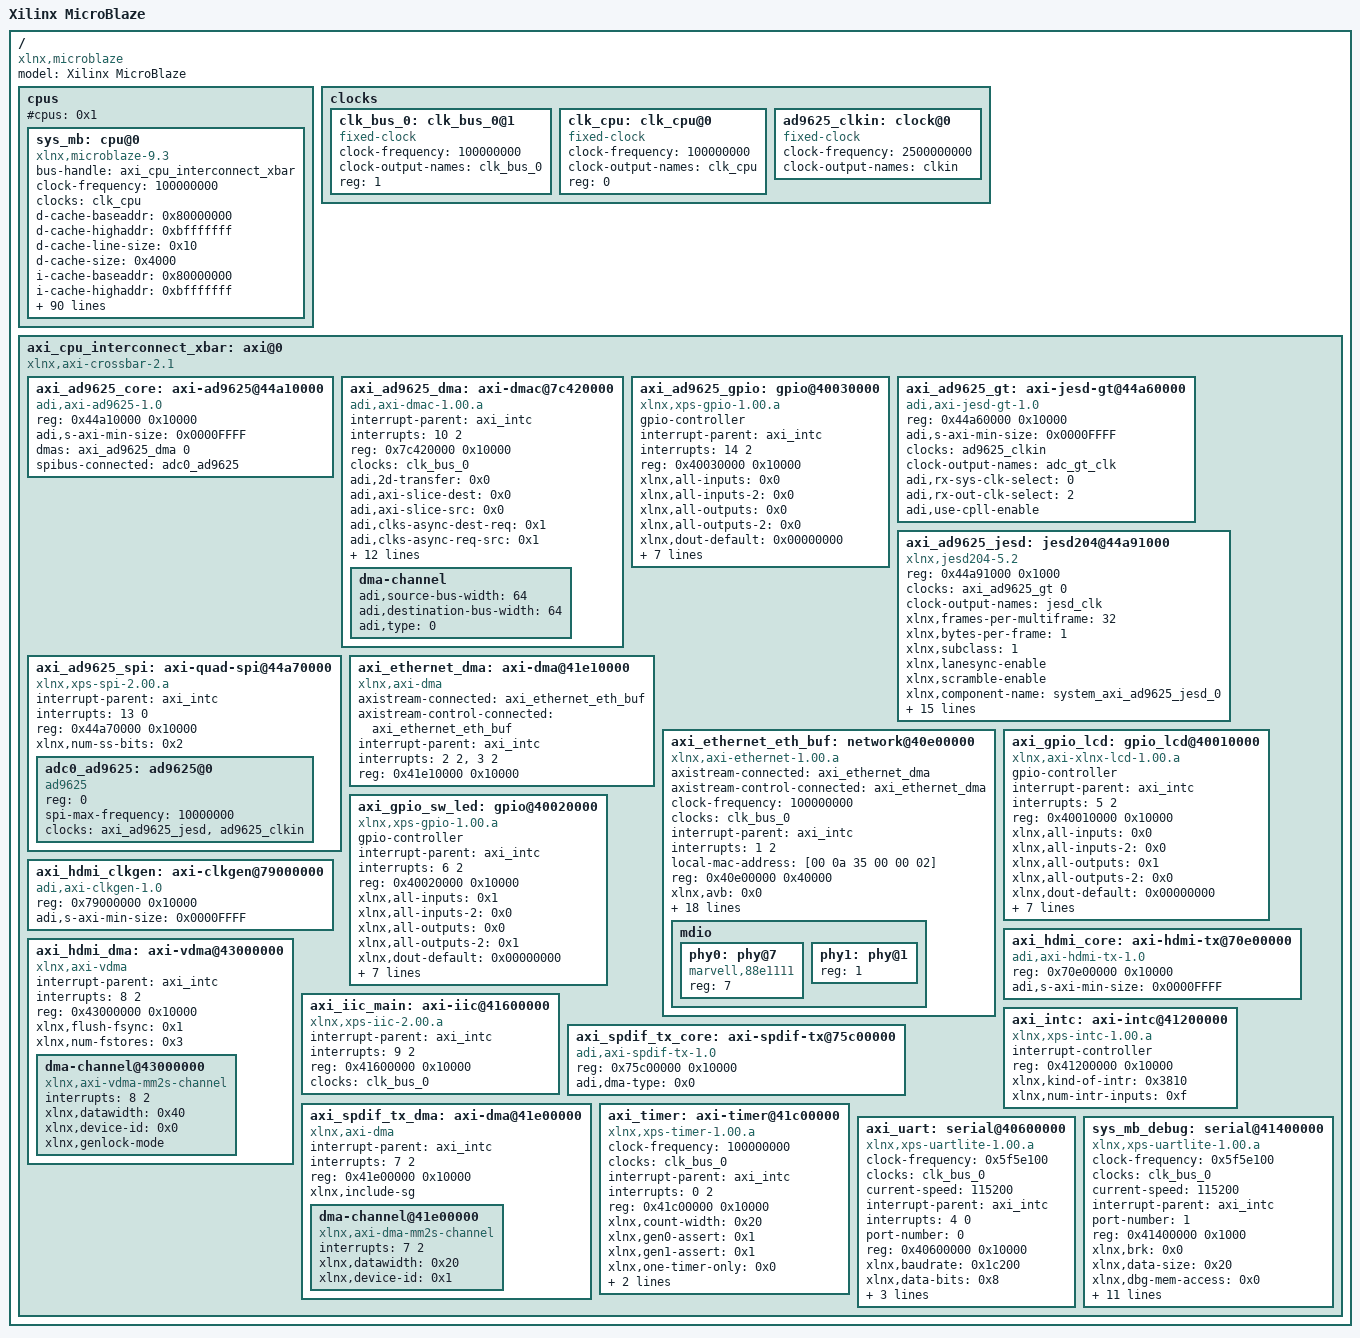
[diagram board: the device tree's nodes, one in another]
/*
 * CAUTION: This file is automatically generated by Xilinx.
 * Version:
 * Today is: Tue Sep  9 10:06:07 2014
*/

/{
	#address-cells = <1>;
	#size-cells = <1>;
	compatible = "xlnx,microblaze";
	model = "Xilinx MicroBlaze";
	cpus {
		#address-cells = <1>;
		#cpus = <0x1>;
		#size-cells = <0>;
		sys_mb: cpu@0 {
			bus-handle = <&axi_cpu_interconnect_xbar>;
			clock-frequency = <100000000>;
			clocks = <&clk_cpu>;
			compatible = "xlnx,microblaze-9.3";
			d-cache-baseaddr = <0x80000000>;
			d-cache-highaddr = <0xbfffffff>;
			d-cache-line-size = <0x10>;
			d-cache-size = <0x4000>;
			device_type = "cpu";
			i-cache-baseaddr = <0x80000000>;
			i-cache-highaddr = <0xbfffffff>;
			i-cache-line-size = <0x20>;
			i-cache-size = <0x4000>;
			interrupt-handle = <&axi_intc>;
			model = "microblaze,9.3";
			timebase-frequency = <100000000>;
			xlnx,addr-tag-bits = <0x10>;
			xlnx,allow-dcache-wr = <0x1>;
			xlnx,allow-icache-wr = <0x1>;
			xlnx,area-optimized = <0x0>;
			xlnx,async-interrupt = <0x1>;
			xlnx,avoid-primitives = <0x0>;
			xlnx,base-vectors = <0x00000000>;
			xlnx,branch-target-cache-size = <0x0>;
			xlnx,cache-byte-size = <0x4000>;
			xlnx,d-axi = <0x1>;
			xlnx,d-lmb = <0x1>;
			xlnx,data-size = <0x20>;
			xlnx,dcache-addr-tag = <0x10>;
			xlnx,dcache-always-used = <0x1>;
			xlnx,dcache-byte-size = <0x4000>;
			xlnx,dcache-data-width = <0x0>;
			xlnx,dcache-force-tag-lutram = <0x0>;
			xlnx,dcache-line-len = <0x4>;
			xlnx,dcache-use-writeback = <0x0>;
			xlnx,dcache-victims = <0x8>;
			xlnx,debug-counter-width = <0x20>;
			xlnx,debug-enabled = <0x1>;
			xlnx,debug-event-counters = <0x5>;
			xlnx,debug-latency-counters = <0x1>;
			xlnx,debug-profile-size = <0x0>;
			xlnx,debug-trace-size = <0x2000>;
			xlnx,div-zero-exception = <0x1>;
			xlnx,dynamic-bus-sizing = <0x0>;
			xlnx,ecc-use-ce-exception = <0x0>;
			xlnx,edge-is-positive = <0x0>;
			xlnx,enable-discrete-ports = <0x0>;
			xlnx,endianness = <0x1>;
			xlnx,fault-tolerant = <0x0>;
			xlnx,fpu-exception = <0x0>;
			xlnx,freq = <0x5f5e100>;
			xlnx,fsl-exception = <0x0>;
			xlnx,fsl-links = <0x0>;
			xlnx,i-axi = <0x0>;
			xlnx,i-lmb = <0x1>;
			xlnx,icache-always-used = <0x1>;
			xlnx,icache-data-width = <0x0>;
			xlnx,icache-force-tag-lutram = <0x0>;
			xlnx,icache-line-len = <0x8>;
			xlnx,icache-streams = <0x1>;
			xlnx,icache-victims = <0x8>;
			xlnx,ill-opcode-exception = <0x1>;
			xlnx,interconnect = <0x2>;
			xlnx,interrupt-is-edge = <0x0>;
			xlnx,lockstep-select = <0x0>;
			xlnx,lockstep-slave = <0x0>;
			xlnx,mmu-dtlb-size = <0x4>;
			xlnx,mmu-itlb-size = <0x2>;
			xlnx,mmu-privileged-instr = <0x0>;
			xlnx,mmu-tlb-access = <0x3>;
			xlnx,mmu-zones = <0x2>;
			xlnx,number-of-pc-brk = <0x1>;
			xlnx,number-of-rd-addr-brk = <0x0>;
			xlnx,number-of-wr-addr-brk = <0x0>;
			xlnx,opcode-0x0-illegal = <0x1>;
			xlnx,optimization = <0x0>;
			xlnx,pc-width = <0x20>;
			xlnx,pvr = <0x2>;
			xlnx,pvr-user1 = <0x00>;
			xlnx,pvr-user2 = <0x00000000>;
			xlnx,reset-msr = <0x00000000>;
			xlnx,sco = <0x0>;
			xlnx,trace = <0x0>;
			xlnx,unaligned-exceptions = <0x1>;
			xlnx,use-barrel = <0x1>;
			xlnx,use-branch-target-cache = <0x0>;
			xlnx,use-config-reset = <0x0>;
			xlnx,use-dcache = <0x1>;
			xlnx,use-div = <0x1>;
			xlnx,use-ext-brk = <0x0>;
			xlnx,use-ext-nm-brk = <0x0>;
			xlnx,use-extended-fsl-instr = <0x0>;
			xlnx,use-fpu = <0x0>;
			xlnx,use-hw-mul = <0x2>;
			xlnx,use-icache = <0x1>;
			xlnx,use-interrupt = <0x1>;
			xlnx,use-mmu = <0x3>;
			xlnx,use-msr-instr = <0x1>;
			xlnx,use-pcmp-instr = <0x1>;
			xlnx,use-reorder-instr = <0x1>;
			xlnx,use-stack-protection = <0x0>;
		} ;
	} ;
	clocks {
		#address-cells = <1>;
		#size-cells = <0>;
		clk_bus_0: clk_bus_0@1 {
			#clock-cells = <0>;
			clock-frequency = <100000000>;
			clock-output-names = "clk_bus_0";
			compatible = "fixed-clock";
			reg = <1>;
		} ;
		clk_cpu: clk_cpu@0 {
			#clock-cells = <0>;
			clock-frequency = <100000000>;
			clock-output-names = "clk_cpu";
			compatible = "fixed-clock";
			reg = <0>;
		} ;
		ad9625_clkin: clock@0 {
			#clock-cells = <0>;
			compatible = "fixed-clock";
			clock-frequency = <2500000000>;
			clock-output-names = "clkin";
		};
	} ;
	axi_cpu_interconnect_xbar: axi@0 {
		#address-cells = <1>;
		#size-cells = <1>;
		compatible = "xlnx,axi-crossbar-2.1", "simple-bus";
		ranges ;
		axi_ad9625_core: axi-ad9625@44a10000 {
			compatible = "adi,axi-ad9625-1.0";
			reg = <0x44a10000 0x10000>;
			adi,s-axi-min-size = <0x0000FFFF>;
			dmas = <&axi_ad9625_dma 0>;
			dma-names = "rx";
			spibus-connected = <&adc0_ad9625>;
		} ;

		axi_ad9625_dma: axi-dmac@7c420000 {
			#dma-cells = <1>;
			compatible = "adi,axi-dmac-1.00.a";
			interrupt-parent = <&axi_intc>;
			interrupts = <10 2>;
			reg = <0x7c420000 0x10000>;
			clocks = <&clk_bus_0>;
			adi,2d-transfer = <0x0>;
			adi,axi-slice-dest = <0x0>;
			adi,axi-slice-src = <0x0>;
			adi,clks-async-dest-req = <0x1>;
			adi,clks-async-req-src = <0x1>;
			adi,clks-async-src-dest = <0x1>;
			adi,cyclic = <0x0>;
			adi,dma-axi-protocol-dest = <0x0>;
			adi,dma-axi-protocol-src = <0x0>;
			adi,dma-data-width-dest = <0x100>;
			adi,dma-data-width-src = <0x100>;
			adi,dma-length-width = <0x18>;
			adi,dma-type-dest = <0x0>;
			adi,dma-type-src = <0x2>;
			adi,fifo-size = <0x4>;
			adi,max-bytes-per-burst = <0x80>;
			adi,sync-transfer-start = <0x1>;

			dma-channel {
				adi,source-bus-width = <64>;
				adi,destination-bus-width = <64>;
				//adi,buswidth = <256>;
				adi,type = <0>;
			};
		} ;
		axi_ad9625_gpio: gpio@40030000 {
			#gpio-cells = <2>;
			compatible = "xlnx,xps-gpio-1.00.a";
			gpio-controller ;
			interrupt-parent = <&axi_intc>;
			interrupts = <14 2>;
			reg = <0x40030000 0x10000>;
			xlnx,all-inputs = <0x0>;
			xlnx,all-inputs-2 = <0x0>;
			xlnx,all-outputs = <0x0>;
			xlnx,all-outputs-2 = <0x0>;
			xlnx,dout-default = <0x00000000>;
			xlnx,dout-default-2 = <0x00000000>;
			xlnx,gpio-width = <0x2>;
			xlnx,gpio2-width = <0x20>;
			xlnx,interrupt-present = <0x1>;
			xlnx,is-dual = <0x0>;
			xlnx,tri-default = <0xFFFFFFFF>;
			xlnx,tri-default-2 = <0xFFFFFFFF>;
		} ;
		axi_ad9625_gt: axi-jesd-gt@44a60000 {
			#clock-cells = <1>;
			compatible = "adi,axi-jesd-gt-1.0";
			reg = <0x44a60000 0x10000>;
			adi,s-axi-min-size = <0x0000FFFF>;

			clocks = <&ad9625_clkin>;
			clock-names = "adc_clk";
			clock-output-names = "adc_gt_clk";

			adi,rx-sys-clk-select = <0>;
			adi,rx-out-clk-select = <2>;
			adi,use-cpll-enable;

		} ;
		axi_ad9625_jesd: jesd204@44a91000 {
			#clock-cells = <0>;
			compatible = "xlnx,jesd204-5.2";
			reg = <0x44a91000 0x1000>;

			clocks = <&axi_ad9625_gt 0>;
			clock-names = "gt_clk";
			clock-output-names = "jesd_clk";

			xlnx,frames-per-multiframe = <32>;
			xlnx,bytes-per-frame = <1>;
			xlnx,subclass = <1>;
			xlnx,lanesync-enable;
			xlnx,scramble-enable;

			xlnx,component-name = "system_axi_ad9625_jesd_0";
			xlnx,drpclk-freq = "200.0";
			xlnx,elaboration-transient-dir = <0x0>;
			xlnx,gt-line-rate = "6.25";
			xlnx,gt-refclk-freq = "156.25";
			xlnx,lanes = <0x8>;
			xlnx,lmfc-buffer-size = <0x6>;
			xlnx,node-is-transmit = <0x0>;
			xlnx,pll-selection = <0x0>;
			xlnx,speedgrade = "-2";
			xlnx,supportlevel = <0x0>;
			xlnx,sysref-sampling-edge = <0x0>;
			xlnx,transceivercontrol = "false";
			xlnx,use-bram = <0x1>;
			xlnx,use-jspat = "false";
			xlnx,use-rpat = "false";
		} ;
		axi_ad9625_spi: axi-quad-spi@44a70000 {
			#address-cells = <1>;
			#size-cells = <0>;
			compatible = "xlnx,xps-spi-2.00.a";
			interrupt-parent = <&axi_intc>;
			interrupts = <13 0>;
			reg = <0x44a70000 0x10000>;
			xlnx,num-ss-bits = <0x2>;

			adc0_ad9625: ad9625@0 {
				#address-cells = <1>;
				#size-cells = <0>;
				compatible = "ad9625";
				reg = <0>;
				spi-max-frequency = <10000000>;
				clocks = <&axi_ad9625_jesd>, <&ad9625_clkin>;
				clock-names = "jesd_clk", "adc_clk";

			};

		} ;
		axi_ethernet_dma: axi-dma@41e10000 {
			axistream-connected = <&axi_ethernet_eth_buf>;
			axistream-control-connected = <&axi_ethernet_eth_buf>;
			compatible = "xlnx,axi-dma";
			interrupt-parent = <&axi_intc>;
			interrupts = <2 2>, <3 2>;
			reg = <0x41e10000 0x10000>;
		} ;
		axi_ethernet_eth_buf: network@40e00000 {
// 			axistream-connected = <&axi_ethernet_dma>;
// 			axistream-control-connected = <&axi_ethernet_dma>;
// 			clock-frequency = <100000000>;
// 			clocks = <&clk_bus_0>;
// 			compatible = "xlnx,axi-ethernet-1.00.a";
// 			device_type = "network";
// 			interrupt-parent = <&axi_intc>;
// 			interrupts = <1 2>;
// 			local-mac-address = [00 0a 35 00 00 00];
// 			reg = <0x40e00000 0x40000>;
// 			phy-handle = <&phy0 &phy1>;
// 			xlnx,avb = <0x0>;
// 			xlnx,enable-lvds = <0x0>;
// 			xlnx,mcast-extend = <0x0>;
// 			xlnx,phy-type = <0x4>;
// 			xlnx,phyaddr = <0x1>;
// 			xlnx,rxcsum = <0x2>;
// 			xlnx,rxmem = <0x1000>;
// 			xlnx,rxvlan-strp = <0x0>;
// 			xlnx,rxvlan-tag = <0x0>;
// 			xlnx,rxvlan-tran = <0x0>;
// 			xlnx,stats = <0x1>;
// 			xlnx,temac-addr-width = <0xc>;
// 			xlnx,txcsum = <0x2>;
// 			xlnx,txmem = <0x1000>;
// 			xlnx,txvlan-strp = <0x0>;
// 			xlnx,txvlan-tag = <0x0>;
// 			xlnx,txvlan-tran = <0x0>;
// 			xlnx,type = <0x1>;


			axistream-connected = <&axi_ethernet_dma>;
			axistream-control-connected = <&axi_ethernet_dma>;
			clock-frequency = <100000000>;
			clocks = <&clk_bus_0>;
			compatible = "xlnx,axi-ethernet-1.00.a";
			device_type = "network";
			interrupt-parent = <&axi_intc>;
			interrupts = <1 2>;
			local-mac-address = [00 0a 35 00 00 02];
			reg = <0x40e00000 0x40000>;
			xlnx,avb = <0x0>;
			xlnx,enable-lvds = <0x0>;
			xlnx,mcast-extend = <0x0>;
			xlnx,phy-type = <0x4>;
			xlnx,phyaddr = <0x1>;
			xlnx,rxcsum = <0x2>;
			xlnx,rxmem = <0x2000>;
			xlnx,rxvlan-strp = <0x0>;
			xlnx,rxvlan-tag = <0x0>;
			xlnx,rxvlan-tran = <0x0>;
			xlnx,stats = <0x1>;
			xlnx,temac-addr-width = <0xc>;
			xlnx,txcsum = <0x2>;
			xlnx,txmem = <0x2000>;
			xlnx,txvlan-strp = <0x0>;
			xlnx,txvlan-tag = <0x0>;
			xlnx,txvlan-tran = <0x0>;
			xlnx,type = <0x1>;
			phy-handle = <&phy0 &phy1>;

			mdio {
				#address-cells = <1>;
				#size-cells = <0>;
				phy0: phy@7 {
					compatible = "marvell,88e1111";
					device_type = "ethernet-phy";
					reg = <7>;
				} ;
				phy1: phy@1 {
					device_type = "ethernet-phy";
					reg = <1>;
				} ;

			} ;
		} ;
		axi_gpio_lcd: gpio_lcd@40010000 {
			#gpio-cells = <2>;
			compatible = "xlnx,axi-xlnx-lcd-1.00.a";
			gpio-controller ;
			interrupt-parent = <&axi_intc>;
			interrupts = <5 2>;
			reg = <0x40010000 0x10000>;
			xlnx,all-inputs = <0x0>;
			xlnx,all-inputs-2 = <0x0>;
			xlnx,all-outputs = <0x1>;
			xlnx,all-outputs-2 = <0x0>;
			xlnx,dout-default = <0x00000000>;
			xlnx,dout-default-2 = <0x00000000>;
			xlnx,gpio-width = <0x7>;
			xlnx,gpio2-width = <0x20>;
			xlnx,interrupt-present = <0x1>;
			xlnx,is-dual = <0x0>;
			xlnx,tri-default = <0xFFFFFFFF>;
			xlnx,tri-default-2 = <0xFFFFFFFF>;
		} ;
		axi_gpio_sw_led: gpio@40020000 {
			#gpio-cells = <2>;
			compatible = "xlnx,xps-gpio-1.00.a";
			gpio-controller ;
			interrupt-parent = <&axi_intc>;
			interrupts = <6 2>;
			reg = <0x40020000 0x10000>;
			xlnx,all-inputs = <0x1>;
			xlnx,all-inputs-2 = <0x0>;
			xlnx,all-outputs = <0x0>;
			xlnx,all-outputs-2 = <0x1>;
			xlnx,dout-default = <0x00000000>;
			xlnx,dout-default-2 = <0x00000000>;
			xlnx,gpio-width = <0xd>;
			xlnx,gpio2-width = <0x8>;
			xlnx,interrupt-present = <0x1>;
			xlnx,is-dual = <0x1>;
			xlnx,tri-default = <0xFFFFFFFF>;
			xlnx,tri-default-2 = <0xFFFFFFFF>;
		} ;
		axi_hdmi_clkgen: axi-clkgen@79000000 {
			compatible = "adi,axi-clkgen-1.0";
			reg = <0x79000000 0x10000>;
			adi,s-axi-min-size = <0x0000FFFF>;
		} ;
		axi_hdmi_core: axi-hdmi-tx@70e00000 {
			compatible = "adi,axi-hdmi-tx-1.0";
			reg = <0x70e00000 0x10000>;
			adi,s-axi-min-size = <0x0000FFFF>;
		} ;
		axi_hdmi_dma: axi-vdma@43000000 {
			compatible = "xlnx,axi-vdma";
			interrupt-parent = <&axi_intc>;
			interrupts = <8 2>;
			reg = <0x43000000 0x10000>;
			xlnx,flush-fsync = <0x1>;
			xlnx,num-fstores = <0x3>;
			dma-channel@43000000 {
				compatible = "xlnx,axi-vdma-mm2s-channel";
				interrupts = <8 2>;
				xlnx,datawidth = <0x40>;
				xlnx,device-id = <0x0>;
				xlnx,genlock-mode ;
			} ;
		} ;
		axi_iic_main: axi-iic@41600000 {
			#address-cells = <1>;
			#size-cells = <0>;
			compatible = "xlnx,xps-iic-2.00.a";
			interrupt-parent = <&axi_intc>;
			interrupts = <9 2>;
			reg = <0x41600000 0x10000>;
			clocks = <&clk_bus_0>;
		} ;
		axi_intc: axi-intc@41200000 {
			#interrupt-cells = <2>;
			compatible = "xlnx,xps-intc-1.00.a";
			interrupt-controller ;
			reg = <0x41200000 0x10000>;
			xlnx,kind-of-intr = <0x3810>;
			xlnx,num-intr-inputs = <0xf>;
		} ;
		axi_spdif_tx_core: axi-spdif-tx@75c00000 {
			compatible = "adi,axi-spdif-tx-1.0";
			reg = <0x75c00000 0x10000>;
			adi,dma-type = <0x0>;
		} ;
		axi_spdif_tx_dma: axi-dma@41e00000 {
			compatible = "xlnx,axi-dma";
			interrupt-parent = <&axi_intc>;
			interrupts = <7 2>;
			reg = <0x41e00000 0x10000>;
			xlnx,include-sg ;
			dma-channel@41e00000 {
				compatible = "xlnx,axi-dma-mm2s-channel";
				interrupts = <7 2>;
				xlnx,datawidth = <0x20>;
				xlnx,device-id = <0x1>;
			} ;
		} ;
		axi_timer: axi-timer@41c00000 {
			clock-frequency = <100000000>;
			clocks = <&clk_bus_0>;
			compatible = "xlnx,xps-timer-1.00.a";
			interrupt-parent = <&axi_intc>;
			interrupts = <0 2>;
			reg = <0x41c00000 0x10000>;
			xlnx,count-width = <0x20>;
			xlnx,gen0-assert = <0x1>;
			xlnx,gen1-assert = <0x1>;
			xlnx,one-timer-only = <0x0>;
			xlnx,trig0-assert = <0x1>;
			xlnx,trig1-assert = <0x1>;
		} ;
		axi_uart: serial@40600000 {
			clock-frequency = <0x5f5e100>;
			clocks = <&clk_bus_0>;
			compatible = "xlnx,xps-uartlite-1.00.a";
			current-speed = <115200>;
			device_type = "serial";
			interrupt-parent = <&axi_intc>;
			interrupts = <4 0>;
			port-number = <0>;
			reg = <0x40600000 0x10000>;
			xlnx,baudrate = <0x1c200>;
			xlnx,data-bits = <0x8>;
			xlnx,odd-parity = <0x0>;
			xlnx,s-axi-aclk-freq-hz-d = <0x64>;
			xlnx,use-parity = <0x0>;
		} ;
		sys_mb_debug: serial@41400000 {
			clock-frequency = <0x5f5e100>;
			clocks = <&clk_bus_0>;
			compatible = "xlnx,xps-uartlite-1.00.a";
			current-speed = <115200>;
			device_type = "serial";
			interrupt-parent = <&axi_intc>;
			//interrupts = <-1 0>;
			port-number = <1>;
			reg = <0x41400000 0x1000>;
			xlnx,brk = <0x0>;
			xlnx,data-size = <0x20>;
			xlnx,dbg-mem-access = <0x0>;
			xlnx,dbg-reg-access = <0x0>;
			xlnx,interconnect = <0x2>;
			xlnx,jtag-chain = <0x2>;
			xlnx,mb-dbg-ports = <0x1>;
			xlnx,trig-in-ports = <0x1>;
			xlnx,trig-out-ports = <0x1>;
			xlnx,use-bscan = <0x0>;
			xlnx,use-config-reset = <0x0>;
			xlnx,use-cross-trigger = <0x0>;
			xlnx,use-uart = <0x1>;
			xlnx,xmtc = <0x0>;
		} ;
	} ;
} ;
